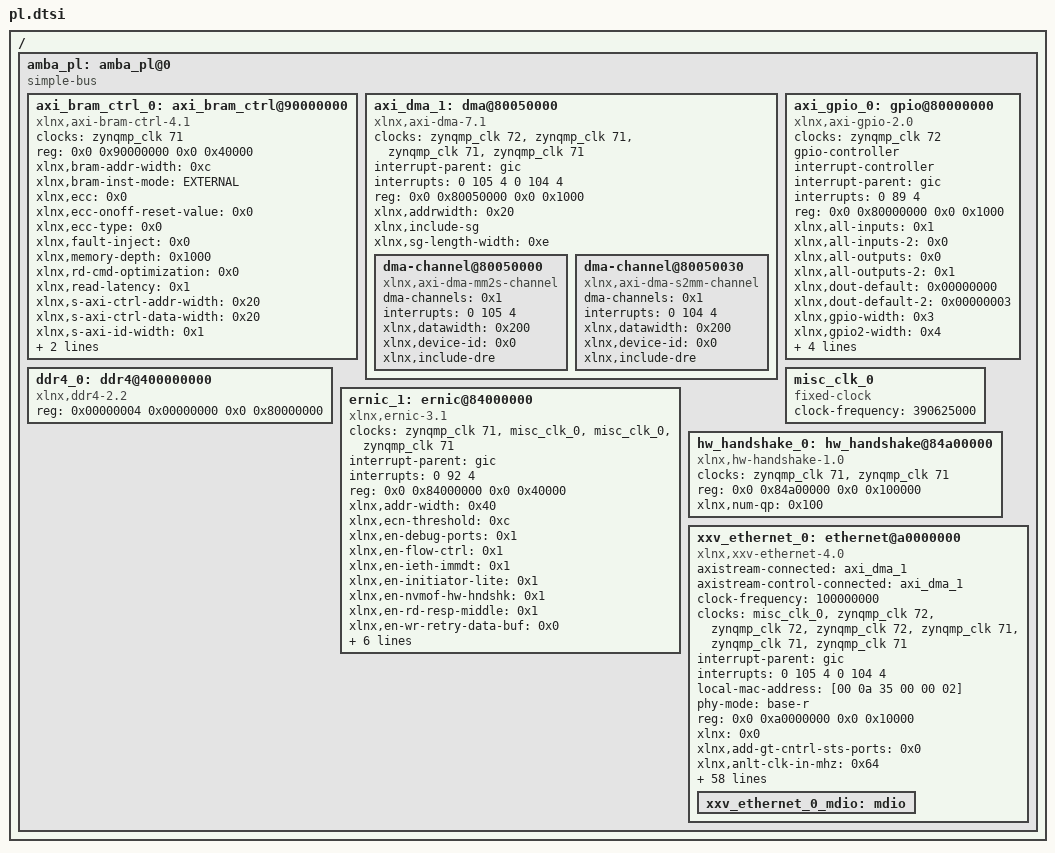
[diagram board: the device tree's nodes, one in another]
/*
 * CAUTION: This file is automatically generated by Xilinx.
 * Version:  
 * Today is: Thu Mar 30 06:41:39 2023
 */


/ {
	amba_pl: amba_pl@0 {
		#address-cells = <2>;
		#size-cells = <2>;
		compatible = "simple-bus";
		ranges ;
		axi_bram_ctrl_0: axi_bram_ctrl@90000000 {
			clock-names = "s_axi_aclk";
			clocks = <&zynqmp_clk 71>;
			compatible = "xlnx,axi-bram-ctrl-4.1";
			reg = <0x0 0x90000000 0x0 0x40000>;
			xlnx,bram-addr-width = <0xc>;
			xlnx,bram-inst-mode = "EXTERNAL";
			xlnx,ecc = <0x0>;
			xlnx,ecc-onoff-reset-value = <0x0>;
			xlnx,ecc-type = <0x0>;
			xlnx,fault-inject = <0x0>;
			xlnx,memory-depth = <0x1000>;
			xlnx,rd-cmd-optimization = <0x0>;
			xlnx,read-latency = <0x1>;
			xlnx,s-axi-ctrl-addr-width = <0x20>;
			xlnx,s-axi-ctrl-data-width = <0x20>;
			xlnx,s-axi-id-width = <0x1>;
			xlnx,s-axi-supports-narrow-burst = <0x0>;
			xlnx,single-port-bram = <0x1>;
		};
		axi_dma_1: dma@80050000 {
			#dma-cells = <1>;
			clock-names = "s_axi_lite_aclk", "m_axi_sg_aclk", "m_axi_mm2s_aclk", "m_axi_s2mm_aclk";
			clocks = <&zynqmp_clk 72>, <&zynqmp_clk 71>, <&zynqmp_clk 71>, <&zynqmp_clk 71>;
			compatible = "xlnx,axi-dma-7.1", "xlnx,axi-dma-1.00.a";
			interrupt-names = "mm2s_introut", "s2mm_introut";
			interrupt-parent = <&gic>;
			interrupts = <0 105 4 0 104 4>;
			reg = <0x0 0x80050000 0x0 0x1000>;
			xlnx,addrwidth = <0x20>;
			xlnx,include-sg ;
			xlnx,sg-length-width = <0xe>;
			dma-channel@80050000 {
				compatible = "xlnx,axi-dma-mm2s-channel";
				dma-channels = <0x1>;
				interrupts = <0 105 4>;
				xlnx,datawidth = <0x200>;
				xlnx,device-id = <0x0>;
				xlnx,include-dre ;
			};
			dma-channel@80050030 {
				compatible = "xlnx,axi-dma-s2mm-channel";
				dma-channels = <0x1>;
				interrupts = <0 104 4>;
				xlnx,datawidth = <0x200>;
				xlnx,device-id = <0x0>;
				xlnx,include-dre ;
			};
		};
		axi_gpio_0: gpio@80000000 {
			#gpio-cells = <3>;
			#interrupt-cells = <2>;
			clock-names = "s_axi_aclk";
			clocks = <&zynqmp_clk 72>;
			compatible = "xlnx,axi-gpio-2.0", "xlnx,xps-gpio-1.00.a";
			gpio-controller ;
			interrupt-controller ;
			interrupt-names = "ip2intc_irpt";
			interrupt-parent = <&gic>;
			interrupts = <0 89 4>;
			reg = <0x0 0x80000000 0x0 0x1000>;
			xlnx,all-inputs = <0x1>;
			xlnx,all-inputs-2 = <0x0>;
			xlnx,all-outputs = <0x0>;
			xlnx,all-outputs-2 = <0x1>;
			xlnx,dout-default = <0x00000000>;
			xlnx,dout-default-2 = <0x00000003>;
			xlnx,gpio-width = <0x3>;
			xlnx,gpio2-width = <0x4>;
			xlnx,interrupt-present = <0x1>;
			xlnx,is-dual = <0x1>;
			xlnx,tri-default = <0xFFFFFFFF>;
			xlnx,tri-default-2 = <0xFFFFFFFF>;
		};
		ddr4_0: ddr4@400000000 {
			compatible = "xlnx,ddr4-2.2";
			reg = <0x00000004 0x00000000 0x0 0x80000000>;
		};
		ernic_1: ernic@84000000 {
			clock-names = "m_axi_aclk", "cmac_rx_clk", "cmac_tx_clk", "s_axi_lite_aclk";
			clocks = <&zynqmp_clk 71>, <&misc_clk_0>, <&misc_clk_0>, <&zynqmp_clk 71>;
			compatible = "xlnx,ernic-3.1";
			interrupt-names = "rnic_intr";
			interrupt-parent = <&gic>;
			interrupts = <0 92 4>;
			reg = <0x0 0x84000000 0x0 0x40000>;
			xlnx,addr-width = <0x40>;
			xlnx,ecn-threshold = <0xc>;
			xlnx,en-debug-ports = <0x1>;
			xlnx,en-flow-ctrl = <0x1>;
			xlnx,en-ieth-immdt = <0x1>;
			xlnx,en-initiator-lite = <0x1>;
			xlnx,en-nvmof-hw-hndshk = <0x1>;
			xlnx,en-rd-resp-middle = <0x1>;
			xlnx,en-wr-retry-data-buf = <0x0>;
			xlnx,max-rd-os = <0x10>;
			xlnx,max-sgl-depth = <0x100>;
			xlnx,max-wr-retry-data-buf-depth = <0x200>;
			xlnx,num-pd = <0x100>;
			xlnx,num-qp = <0x100>;
			xlnx,osq-psn-width = <0x10>;
		};
		misc_clk_0: misc_clk_0 {
			#clock-cells = <0>;
			clock-frequency = <390625000>;
			compatible = "fixed-clock";
		};
		hw_handshake_0: hw_handshake@84a00000 {
			clock-names = "s_axi_lite_aclk", "m_axi_clk";
			clocks = <&zynqmp_clk 71>, <&zynqmp_clk 71>;
			compatible = "xlnx,hw-handshake-1.0";
			reg = <0x0 0x84a00000 0x0 0x100000>;
			xlnx,num-qp = <0x100>;
		};
		xxv_ethernet_0: ethernet@a0000000 {
			axistream-connected = <&axi_dma_1>;
			axistream-control-connected = <&axi_dma_1>;
			clock-frequency = <100000000>;
			clock-names = "rx_core_clk", "dclk", "s_axi_aclk", "s_axi_lite_aclk", "m_axi_sg_aclk", "m_axi_mm2s_aclk", "m_axi_s2mm_aclk";
			clocks = <&misc_clk_0>,  <&zynqmp_clk 72>,  <&zynqmp_clk 72>, <&zynqmp_clk 72>, <&zynqmp_clk 71>, <&zynqmp_clk 71>, <&zynqmp_clk 71>;
			compatible = "xlnx,xxv-ethernet-4.0", "xlnx,xxv-ethernet-1.0";
			device_type = "network";
			interrupt-names = "mm2s_introut", "s2mm_introut";
			interrupt-parent = <&gic>;
			interrupts = <0 105 4 0 104 4>;
			local-mac-address = [00 0a 35 00 00 02];
			phy-mode = "base-r";
			reg = <0x0 0xa0000000 0x0 0x10000>;
			xlnx = <0x0>;
			xlnx,add-gt-cntrl-sts-ports = <0x0>;
			xlnx,anlt-clk-in-mhz = <0x64>;
			xlnx,axis-tdata-width = <0x40>;
			xlnx,axis-tkeep-width = <0x7>;
			xlnx,base-r-kr = "BASE-R";
			xlnx,channel-ids = <0x1>;
			xlnx,clocking = "Asynchronous";
			xlnx,cmac-core-select = "CMACE4_X0Y0";
			xlnx,core = "Ethernet MAC+PCS/PMA 64-bit";
			xlnx,data-path-interface = "AXI Stream";
			xlnx,enable-datapath-parity = <0x0>;
			xlnx,enable-gt-board-interface = <0x0>;
			xlnx,enable-pipeline-reg = <0x0>;
			xlnx,enable-preemption = <0x0>;
			xlnx,enable-preemption-fifo = <0x0>;
			xlnx,enable-rx-flow-control-logic = <0x0>;
			xlnx,enable-time-stamping = <0x0>;
			xlnx,enable-tx-flow-control-logic = <0x1>;
			xlnx,enable-vlane-adjust-mode = <0x0>;
			xlnx,family-chk = "zynquplus";
			xlnx,fast-sim-mode = <0x0>;
			xlnx,gt-diffctrl-width = <0x4>;
			xlnx,gt-drp-clk = "100.00";
			xlnx,gt-group-select = "Quad X0Y0";
			xlnx,gt-location = <0x1>;
			xlnx,gt-ref-clk-freq = "322.265625";
			xlnx,gt-type = "GTY";
			xlnx,gtm-group-select = "NA";
			xlnx,include-auto-neg-lt-logic = "None";
			xlnx,include-axi4-interface = <0x1>;
			xlnx,include-dre ;
			xlnx,include-fec-logic = <0x0>;
			xlnx,include-hybrid-cmac-rsfec-logic = <0x0>;
			xlnx,include-rsfec-logic = <0x0>;
			xlnx,include-shared-logic = <0x1>;
			xlnx,include-statistics-counters = <0x1>;
			xlnx,include-user-fifo = <0x1>;
			xlnx,ins-loss-nyq = <0x1e>;
			xlnx,lane1-gt-loc = "X0Y24";
			xlnx,lane2-gt-loc = "NA";
			xlnx,lane3-gt-loc = "NA";
			xlnx,lane4-gt-loc = "NA";
			xlnx,line-rate = <0x19>;
			xlnx,mii-ctrl-width = <0x4>;
			xlnx,mii-data-width = <0x20>;
			xlnx,num-of-cores = <0x1>;
			xlnx,num-queues = /bits/ 16 <0x1>;
			xlnx,ptp-clocking-mode = <0x0>;
			xlnx,ptp-operation-mode = <0x2>;
			xlnx,runtime-switch = <0x0>;
			xlnx,rx-eq-mode = "AUTO";
			xlnx,rxmem = <0x2580>;
			xlnx,statistics-regs-type = <0x0>;
			xlnx,switch-1-10-25g = <0x0>;
			xlnx,sys-clk = <0xfa0>;
			xlnx,tx-latency-adjust = <0x0>;
			xlnx,tx-total-bytes-width = <0x4>;
			xlnx,xgmii-interface = <0x1>;
			zclock-names = "NULL";
			zclocks = "NULL";
			xxv_ethernet_0_mdio: mdio {
				#address-cells = <1>;
				#size-cells = <0>;
			};
		};
	};
};
